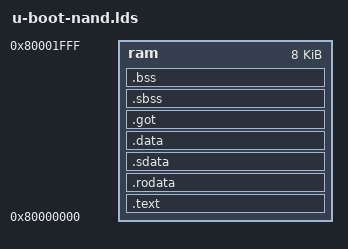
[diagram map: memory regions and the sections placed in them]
/*
 * (C) Copyright 2006
 * Ingenic Semiconductor, <jlwei@ingenic.cn>
 *
 * This program is free software; you can redistribute it and/or
 * modify it under the terms of the GNU General Public License as
 * published by the Free Software Foundation; either version 2 of
 * the License, or (at your option) any later version.
 *
 * This program is distributed in the hope that it will be useful,
 * but WITHOUT ANY WARRANTY; without even the implied warranty of
 * MERCHANTABILITY or FITNESS FOR A PARTICULAR PURPOSE.  See the
 * GNU General Public License for more details.
 *
 * You should have received a copy of the GNU General Public License
 * along with this program; if not, write to the Free Software
 * Foundation, Inc., 59 Temple Place, Suite 330, Boston,
 * MA 02111-1307 USA
 */
OUTPUT_ARCH(mips)
ENTRY(_start)
MEMORY
{
	ram	: ORIGIN = 0x80000000 , LENGTH = 0x2000
}

SECTIONS
{
	. = ALIGN(4);
	.text : { *(.text*) } > ram

	. = ALIGN(4);
	.rodata : { *(.rodata*) } > ram

	. = ALIGN(4);
	.sdata : { *(.sdata*) } > ram

	. = ALIGN(4);
	.data : { *(.data*) *(.scommon*) *(.reginfo*) } > ram

	_gp = ALIGN(16);
	.got : { *(.got*) } > ram

	. = ALIGN(4);
	.sbss : { *(.sbss*) } > ram
	.bss : { *(.bss*) } > ram
	. = ALIGN (4);
}

